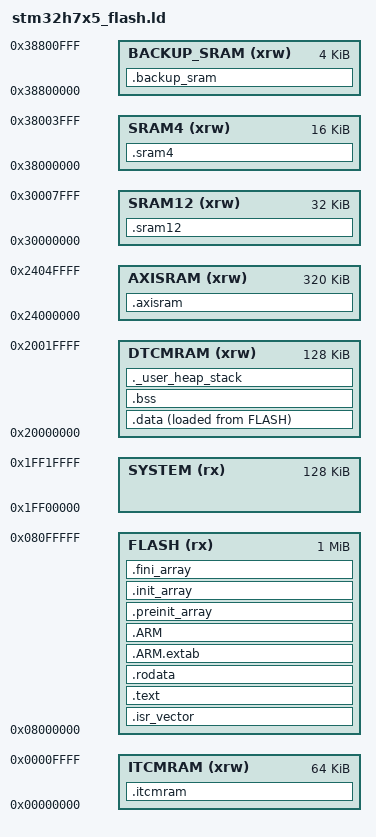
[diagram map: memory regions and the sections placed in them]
/*
******************************************************************************
**

**  File        : LinkerScript.ld
**
**  Author		: Auto-generated by System Workbench for STM32
**
**  Abstract    : Linker script for STM32H735ZGTx series
**                1024Kbytes FLASH and 560Kbytes RAM
**
**                Set heap size, stack size and stack location according
**                to application requirements.
**
**                Set memory bank area and size if external memory is used.
**
**  Target      : STMicroelectronics STM32
**
**  Distribution: The file is distributed “as is,” without any warranty
**                of any kind.
**
*****************************************************************************
** @attention
**
** <h2><center>&copy; COPYRIGHT(c) 2019 STMicroelectronics</center></h2>
**
** Redistribution and use in source and binary forms, with or without modification,
** are permitted provided that the following conditions are met:
**   1. Redistributions of source code must retain the above copyright notice,
**      this list of conditions and the following disclaimer.
**   2. Redistributions in binary form must reproduce the above copyright notice,
**      this list of conditions and the following disclaimer in the documentation
**      and/or other materials provided with the distribution.
**   3. Neither the name of STMicroelectronics nor the names of its contributors
**      may be used to endorse or promote products derived from this software
**      without specific prior written permission.
**
** THIS SOFTWARE IS PROVIDED BY THE COPYRIGHT HOLDERS AND CONTRIBUTORS "AS IS"
** AND ANY EXPRESS OR IMPLIED WARRANTIES, INCLUDING, BUT NOT LIMITED TO, THE
** IMPLIED WARRANTIES OF MERCHANTABILITY AND FITNESS FOR A PARTICULAR PURPOSE ARE
** DISCLAIMED. IN NO EVENT SHALL THE COPYRIGHT HOLDER OR CONTRIBUTORS BE LIABLE
** FOR ANY DIRECT, INDIRECT, INCIDENTAL, SPECIAL, EXEMPLARY, OR CONSEQUENTIAL
** DAMAGES (INCLUDING, BUT NOT LIMITED TO, PROCUREMENT OF SUBSTITUTE GOODS OR
** SERVICES; LOSS OF USE, DATA, OR PROFITS; OR BUSINESS INTERRUPTION) HOWEVER
** CAUSED AND ON ANY THEORY OF LIABILITY, WHETHER IN CONTRACT, STRICT LIABILITY,
** OR TORT (INCLUDING NEGLIGENCE OR OTHERWISE) ARISING IN ANY WAY OUT OF THE USE
** OF THIS SOFTWARE, EVEN IF ADVISED OF THE POSSIBILITY OF SUCH DAMAGE.
**
*****************************************************************************
*/

/* Entry Point */
ENTRY(Reset_Handler)

/* Highest address of the user mode stack */
enter_bootloader_mode = 0x38001FFC;
_estack = 0x20020000;    /* end of RAM */
_app_start = 0x08020000; /* Reserve Sector 0(128K) for bootloader */

/* Generate a link error if heap and stack don't fit into RAM */
_Min_Heap_Size = 0x200;      /* required amount of heap  */
_Min_Stack_Size = 0x400; /* required amount of stack */

/* Specify the memory areas */
MEMORY
{
/* RAM */
BACKUP_SRAM (xrw)  : ORIGIN = 0x38800000, LENGTH = 4K /* Backup SRAM(4kb) */
SRAM4 (xrw)        : ORIGIN = 0x38000000, LENGTH = 16K /* SRAM4(16kb) best for BDMA and SDMMC1*/
SRAM12 (xrw)       : ORIGIN = 0x30000000, LENGTH = 32K /* SRAM1(16kb) + SRAM2(16kb), not for BDMA or SDMMC1 */
AXISRAM (xrw)      : ORIGIN = 0x24000000, LENGTH = 320K /* AXI SRAM */
DTCMRAM (xrw)      : ORIGIN = 0x20000000, LENGTH = 128K /* DTCM */

/* Code */
SYSTEM (rx)        : ORIGIN = 0x1FF00000, LENGTH = 128K /* System memory */
FLASH (rx)         : ORIGIN = 0x08000000, LENGTH = 1024K
ITCMRAM (xrw)      : ORIGIN = 0x00000000, LENGTH = 64K
}

/* Define output sections */
SECTIONS
{
  /* The startup code goes first into FLASH */
  .isr_vector :
  {
    . = ALIGN(4);
    KEEP(*(.isr_vector)) /* Startup code */
    . = ALIGN(4);
  } >FLASH

  /* The program code and other data goes into FLASH */
  .text :
  {
    . = ALIGN(4);
    *(.text)           /* .text sections (code) */
    *(.text*)          /* .text* sections (code) */
    *(.glue_7)         /* glue arm to thumb code */
    *(.glue_7t)        /* glue thumb to arm code */
    *(.eh_frame)

    KEEP (*(.init))
    KEEP (*(.fini))

    . = ALIGN(4);
    _etext = .;        /* define a global symbols at end of code */
  } >FLASH

  /* Constant data goes into FLASH */
  .rodata :
  {
    . = ALIGN(4);
    *(.rodata)         /* .rodata sections (constants, strings, etc.) */
    *(.rodata*)        /* .rodata* sections (constants, strings, etc.) */
    . = ALIGN(4);
  } >FLASH

  .ARM.extab   : { *(.ARM.extab* .gnu.linkonce.armextab.*) } >FLASH
  .ARM : {
    __exidx_start = .;
    *(.ARM.exidx*)
    __exidx_end = .;
  } >FLASH

  .preinit_array     :
  {
    PROVIDE_HIDDEN (__preinit_array_start = .);
    KEEP (*(.preinit_array*))
    PROVIDE_HIDDEN (__preinit_array_end = .);
  } >FLASH
  .init_array :
  {
    PROVIDE_HIDDEN (__init_array_start = .);
    KEEP (*(SORT(.init_array.*)))
    KEEP (*(.init_array*))
    PROVIDE_HIDDEN (__init_array_end = .);
  } >FLASH
  .fini_array :
  {
    PROVIDE_HIDDEN (__fini_array_start = .);
    KEEP (*(SORT(.fini_array.*)))
    KEEP (*(.fini_array*))
    PROVIDE_HIDDEN (__fini_array_end = .);
  } >FLASH

  /* used by the startup to initialize data */
  _sidata = LOADADDR(.data);

  /* Initialized data sections goes into RAM, load LMA copy after code */
  .data :
  {
    . = ALIGN(4);
    _sdata = .;        /* create a global symbol at data start */
    *(.data)           /* .data sections */
    *(.data*)          /* .data* sections */

    . = ALIGN(4);
    _edata = .;        /* define a global symbol at data end */
  } >DTCMRAM AT> FLASH


  /* Uninitialized data section */
  . = ALIGN(4);
  .bss :
  {
    /* This is used by the startup in order to initialize the .bss secion */
    _sbss = .;         /* define a global symbol at bss start */
    __bss_start__ = _sbss;
    *(.bss)
    *(.bss*)
    *(COMMON)

    . = ALIGN(4);
    _ebss = .;         /* define a global symbol at bss end */
    __bss_end__ = _ebss;
  } >DTCMRAM

  /* User_heap_stack section, used to check that there is enough RAM left */
  ._user_heap_stack :
  {
    . = ALIGN(8);
    PROVIDE ( end = . );
    PROVIDE ( _end = . );
    . = . + _Min_Heap_Size;
    . = . + _Min_Stack_Size;
    . = ALIGN(8);
  } >DTCMRAM

  .itcmram (NOLOAD) :
  {
    . = ALIGN(4);
    *(.itcmram*)
  } >ITCMRAM

  .axisram (NOLOAD) :
  {
    . = ALIGN(4);
    *(.axisram*)
  } >AXISRAM

  .sram12 (NOLOAD) :
  {
    . = ALIGN(4);
    *(.sram12*)
  } >SRAM12

  .sram4 (NOLOAD) :
  {
    . = ALIGN(4);
    *(.sram4*)
  } >SRAM4

  .backup_sram (NOLOAD) :
  {
    . = ALIGN(4);
    *(.backup_sram*)
  } >BACKUP_SRAM

  .ARM.attributes 0 : { *(.ARM.attributes) }
}


